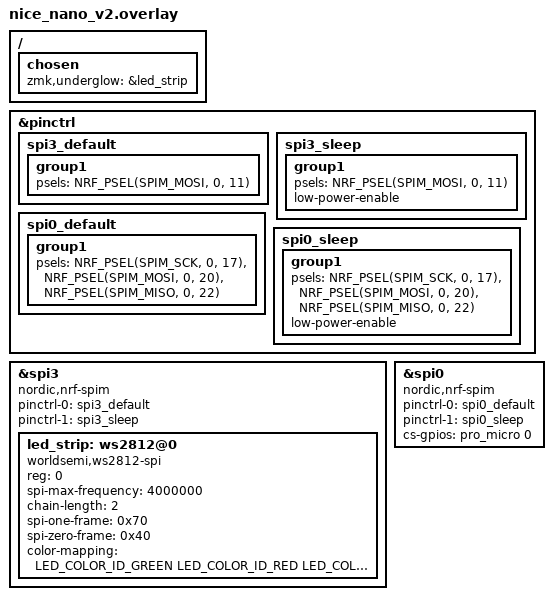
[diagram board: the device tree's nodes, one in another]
#include <dt-bindings/led/led.h>

/* Set LED and dislay details.

Set pins

-   Smart LEDs (which sit on SPI)
-   Display

Using two-part pin numbers at
https://nicekeyboards.com/docs/nice-nano/pinout-schematic/

Set type of smart LED and display.
*/

&pinctrl {

    /* SPI for Smart LEDs */

    spi3_default: spi3_default {
        group1 {
            psels = <NRF_PSEL(SPIM_MOSI, 0, 11)>;
        };
    };

    spi3_sleep: spi3_sleep {
        group1 {
            psels = <NRF_PSEL(SPIM_MOSI, 0, 11)>;
            low-power-enable;
        };
    };

    /* SPI for display */

    spi0_default: spi0_default {
        group1 {
            psels = <NRF_PSEL(SPIM_SCK, 0, 17)>,
            <NRF_PSEL(SPIM_MOSI, 0, 20)>,
            <NRF_PSEL(SPIM_MISO, 0, 22)>; /* Optional. Not used by nice!view. */
        };
    };

    spi0_sleep: spi0_sleep {
        group1 {
            psels = <NRF_PSEL(SPIM_SCK, 0, 17)>,
            <NRF_PSEL(SPIM_MOSI, 0, 20)>,
            <NRF_PSEL(SPIM_MISO, 0, 22)>; /* Optional. Not used by nice!view. */
            low-power-enable;
        };
    };
};

/* SPI: LED */
&spi3 {
  compatible = "nordic,nrf-spim";
  status = "okay";

  pinctrl-0 = <&spi3_default>;
  pinctrl-1 = <&spi3_sleep>;
  pinctrl-names = "default", "sleep";

  led_strip: ws2812@0 {
    compatible = "worldsemi,ws2812-spi";

    /* SPI */
    reg = <0>; /* ignored, but necessary for SPI bindings */
    spi-max-frequency = <4000000>;

    /* WS2812 */
    chain-length = <2>; /* number of LEDs */
    spi-one-frame = <0x70>;
    spi-zero-frame = <0x40>;
    color-mapping = <LED_COLOR_ID_GREEN
                          LED_COLOR_ID_RED
                          LED_COLOR_ID_BLUE>;
  };
};

/* SPI: Display */
nice_view_spi: &spi0 {
  compatible = "nordic,nrf-spim";
  pinctrl-0 = <&spi0_default>;
  pinctrl-1 = <&spi0_sleep>;
  pinctrl-names = "default", "sleep";
  cs-gpios = <&pro_micro 0 GPIO_ACTIVE_HIGH>;
};

/ {
    chosen {
        zmk,underglow = &led_strip;
    };
};
